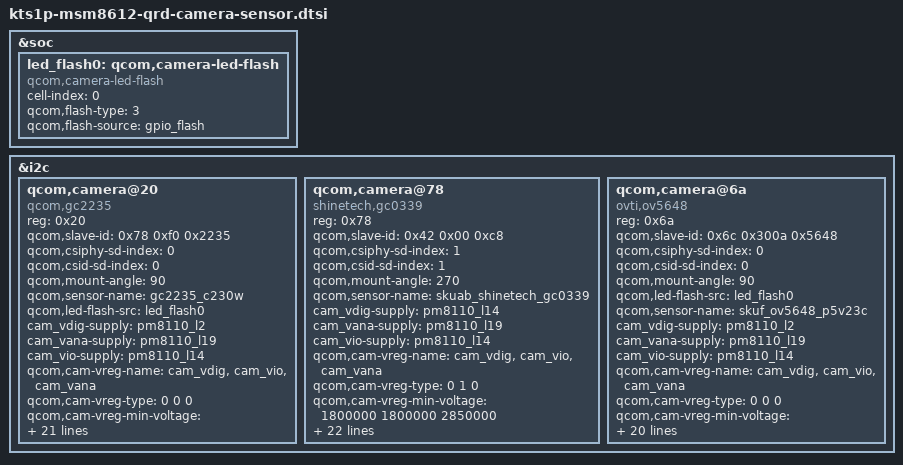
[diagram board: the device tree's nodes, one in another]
/*
 * Copyright (c) 2013, The Linux Foundation. All rights reserved.
 *
 * This program is free software; you can redistribute it and/or modify
 * it under the terms of the GNU General Public License version 2 and
 * only version 2 as published by the Free Software Foundation.
 *
 * This program is distributed in the hope that it will be useful,
 * but WITHOUT ANY WARRANTY; without even the implied warranty of
 * MERCHANTABILITY or FITNESS FOR A PARTICULAR PURPOSE.  See the
 * GNU General Public License for more details.
 */

&soc {
	led_flash0: qcom,camera-led-flash {
		cell-index = <0>;
		compatible = "qcom,camera-led-flash";
		qcom,flash-type = <3>;
		qcom,flash-source = <&gpio_flash>;
	};
};

&i2c {
	/* C230W back camera */
	qcom,camera@20 {
		compatible = "qcom,gc2235";
		reg = <0x20>;
		qcom,slave-id = <0x78 0xf0 0x2235>;
		qcom,csiphy-sd-index = <0>;
		qcom,csid-sd-index = <0>;
		qcom,mount-angle = <90>;
		qcom,sensor-name = "gc2235_c230w";
		qcom,led-flash-src = <&led_flash0>;
		cam_vdig-supply = <&pm8110_l2>;
		cam_vana-supply = <&pm8110_l19>;
		cam_vio-supply = <&pm8110_l14>;
		qcom,cam-vreg-name = "cam_vdig", "cam_vio", "cam_vana";
		qcom,cam-vreg-type = <0 0 0>;
		qcom,cam-vreg-min-voltage = <1200000 1800000 2850000>;
		qcom,cam-vreg-max-voltage = <1200000 1800000 2850000>;
		qcom,cam-vreg-op-mode = <200000 8000 80000>;
		qcom,gpio-no-mux = <0>;
		gpios = <&msmgpio 13 0>,
			<&msmgpio 21 0>,
			<&msmgpio 20 0>,
			<&msmgpio 70 0>,
			<&msmgpio 71 0>;
		qcom,gpio-reset = <1>;
		qcom,gpio-standby = <2>;
		qcom,gpio-vana = <3>;
		qcom,gpio-vdig = <4>;
		qcom,gpio-req-tbl-num = <0 1 2 3 4>;
		qcom,gpio-req-tbl-flags = <1 0 0 0 0>;
		qcom,gpio-req-tbl-label = "CAMIF_MCLK",
			"CAM_RESET1",
			"CAM_STANDBY",
			"CAM_VANA",
			"CAM_VDIG";
		qcom,csi-lane-assign = <0x4320>;
		qcom,csi-lane-mask = <0x7>;
		qcom,sensor-position = <0>;
		qcom,sensor-mode = <1>;
		qcom,sensor-type = <0>;
		qcom,cci-master = <0>;
	};

	/* C230Wxx front camera */
	qcom,camera@78 {
		compatible = "shinetech,gc0339";
		reg = <0x78>;
		qcom,slave-id = <0x42 0x00 0xc8>;
		qcom,csiphy-sd-index = <1>;
		qcom,csid-sd-index = <1>;
		qcom,mount-angle = <270>;
		qcom,sensor-name = "skuab_shinetech_gc0339";
		cam_vdig-supply = <&pm8110_l14>;
		cam_vana-supply = <&pm8110_l19>;
		cam_vio-supply = <&pm8110_l14>;
		qcom,cam-vreg-name = "cam_vdig", "cam_vio", "cam_vana";
		qcom,cam-vreg-type = <0 1 0>;
		qcom,cam-vreg-min-voltage = <1800000 1800000 2850000>;
		qcom,cam-vreg-max-voltage = <1800000 1800000 2850000>;
		qcom,cam-vreg-op-mode = <200000 0 80000>;
		qcom,gpio-no-mux = <0>;
		gpios = <&msmgpio 14 0>,
				<&msmgpio 85 0>,
				<&msmgpio 70 0>,
				<&msmgpio 71 0>,
				<&msmgpio 15 0>;
		qcom,gpio-standby = <1>;
		qcom,gpio-vana = <2>;
		qcom,gpio-vdig = <3>;
		qcom,gpio-reset = <4>;
		qcom,gpio-req-tbl-num = <0 1 2 3 4>;
		qcom,gpio-req-tbl-flags = <1 0 0 0 0>;
		qcom,gpio-req-tbl-label = "CAMIF_MCLK",
				"CAM_STANDBY",
				"CAM_VANA",
				"CAM_VDIG",
				"CAM_RESET";
		qcom,gpio-set-tbl-num = <1 1>;
		qcom,gpio-set-tbl-flags = <0 2>;
		qcom,gpio-set-tbl-delay = <1000 4000>;
		qcom,csi-lane-assign = <0xe4>;
		qcom,csi-lane-mask = <0x3>;
		qcom,sensor-position = <1>;
		qcom,sensor-mode = <1>;
		qcom,cci-master = <0>;
		status = "ok";
	};

	/* C230WJA (KTS1P) back camera */
	qcom,camera@6a {
		compatible = "ovti,ov5648";
		reg = <0x6a>;
		qcom,slave-id = <0x6c 0x300a 0x5648>;
		qcom,csiphy-sd-index = <0>;
		qcom,csid-sd-index = <0>;
//		qcom,eeprom-src = <&eeprom2>;
		qcom,mount-angle = <90>;
		qcom,led-flash-src = <&led_flash0>;
		qcom,sensor-name = "skuf_ov5648_p5v23c";
		cam_vdig-supply = <&pm8110_l2>;
		cam_vana-supply = <&pm8110_l19>;
		cam_vio-supply = <&pm8110_l14>;
		qcom,cam-vreg-name = "cam_vdig", "cam_vio", "cam_vana";
		qcom,cam-vreg-type = <0 0 0>;
		qcom,cam-vreg-min-voltage = <1200000 1800000 2850000>;
		qcom,cam-vreg-max-voltage = <1200000 1800000 2850000>;
		qcom,cam-vreg-op-mode = <200000 8000 80000>;
		qcom,gpio-no-mux = <0>;
		gpios = <&msmgpio 13 0>,
				<&msmgpio 21 0>,
				<&msmgpio 20 0>,
				<&msmgpio 70 0>,
				<&msmgpio 71 0>;
		qcom,gpio-reset = <1>;
		qcom,gpio-standby = <2>;
		qcom,gpio-vana = <3>;
		qcom,gpio-vdig = <4>;
		qcom,gpio-req-tbl-num = <0 1 2 3 4>;
		qcom,gpio-req-tbl-flags = <1 0 0 0 0>;
		qcom,gpio-req-tbl-label = "CAMIF_MCLK",
				"CAM_RESET1",
				"CAM_STANDBY",
				"CAM_VANA",
				"CAM_VDIG";
//		qcom,gpio-set-tbl-num = <0 1 2 3 4>;
//		qcom,gpio-set-tbl-flags = <1 0 0 0>;
//		qcom,gpio-set-tbl-delay = <1000 4000>;
		qcom,csi-lane-assign = <0x4320>;
		qcom,csi-lane-mask = <0x3>;
		qcom,sensor-position = <0>;
		qcom,sensor-mode = <1>;
		qcom,cci-master = <0>;
//		status = "ok";
	};
	
};
